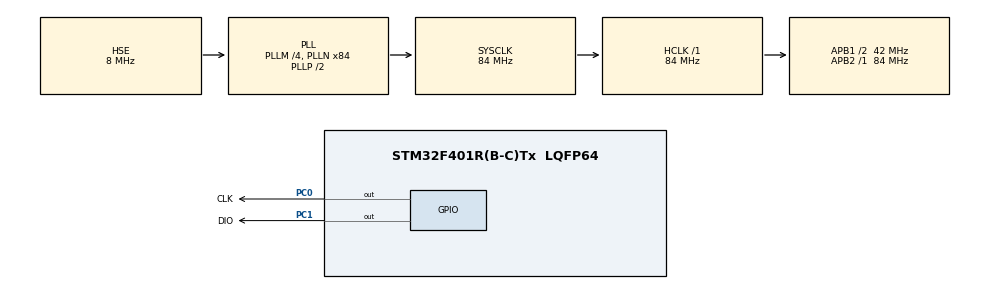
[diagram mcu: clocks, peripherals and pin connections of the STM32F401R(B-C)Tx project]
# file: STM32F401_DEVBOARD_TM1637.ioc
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Mcu.Family=STM32F4
Mcu.Name=STM32F401R(B-C)Tx
Mcu.Package=LQFP64
NVIC.PriorityGroup=NVIC_PRIORITYGROUP_4
PA13.Mode=Serial_Wire
PA13.Signal=SYS_JTMS-SWDIO
PA14.Mode=Serial_Wire
PA14.Signal=SYS_JTCK-SWCLK
PC0.GPIO_Label=CLK
PC0.GPIO_PuPd=GPIO_PULLUP
PC0.Signal=GPIO_Output
PC1.GPIO_Label=DIO
PC1.GPIO_PuPd=GPIO_PULLUP
PC1.Signal=GPIO_Output
PC14-OSC32_IN.Mode=LSE-External-Oscillator
PC14-OSC32_IN.Signal=RCC_OSC32_IN
PC15-OSC32_OUT.Mode=LSE-External-Oscillator
PC15-OSC32_OUT.Signal=RCC_OSC32_OUT
PH0\ -\ OSC_IN.Mode=HSE-External-Oscillator
PH0\ -\ OSC_IN.Signal=RCC_OSC_IN
PH1\ -\ OSC_OUT.Mode=HSE-External-Oscillator
PH1\ -\ OSC_OUT.Signal=RCC_OSC_OUT
ProjectManager.HeapSize=0x200
ProjectManager.StackSize=0x400
ProjectManager.TargetToolchain=STM32CubeIDE
RCC.48MHZClocksFreq_Value=42000000
RCC.AHBFreq_Value=84000000
RCC.APB1CLKDivider=RCC_HCLK_DIV2
RCC.APB1Freq_Value=42000000
RCC.APB1TimFreq_Value=84000000
RCC.APB2Freq_Value=84000000
RCC.APB2TimFreq_Value=84000000
RCC.CortexFreq_Value=84000000
RCC.HCLKFreq_Value=84000000
RCC.HSE_VALUE=8000000
RCC.HSI_VALUE=16000000
RCC.PLLM=4
RCC.PLLN=84
RCC.PLLSourceVirtual=RCC_PLLSOURCE_HSE
RCC.SYSCLKFreq_VALUE=84000000
RCC.SYSCLKSource=RCC_SYSCLKSOURCE_PLLCLK
RCC.VCOOutputFreq_Value=168000000
board=custom

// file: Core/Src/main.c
/* USER CODE BEGIN Header */
/**
  ******************************************************************************
  * @file           : main.c
  * @brief          : Main program body
  ******************************************************************************
  * @attention
  *
  * Copyright (c) 2025 STMicroelectronics.
  * All rights reserved.
  *
  * This software is licensed under terms that can be found in the LICENSE file
  * in the root directory of this software component.
  * If no LICENSE file comes with this software, it is provided AS-IS.
  *
  ******************************************************************************
  */
/* USER CODE END Header */
#include "main.h"
#include "gpio.h"

/* USER CODE BEGIN Includes */

#include "TM1637/TM1637.h"

/* USER CODE END Includes */

/* USER CODE BEGIN PM */

#define BRIGHTNESS 05

/* USER CODE END PM */

/* USER CODE BEGIN PV */

TM1637_t TM1637;
char TxBuffer[5];

/* USER CODE END PV */

void SystemClock_Config(void);

int main(void)
{

  /* MCU Configuration--------------------------------------------------------*/

  /* Reset of all peripherals, Initializes the Flash interface and the Systick. */
  HAL_Init();

  /* Configure the system clock */
  SystemClock_Config();

  /* Initialize all configured peripherals */
  MX_GPIO_Init();

  /* Infinite loop */
  /* USER CODE BEGIN WHILE */

  TM1637_init(&TM1637, CLK_GPIO_Port, CLK_Pin, DIO_GPIO_Port, DIO_Pin); // инициализация портов дисплея
  TM1637_set(&TM1637, BRIGHTNESS);
  TM1637_point(&TM1637, false);                             // точки отключаем

  while (1)
  {
    /* USER CODE END WHILE */

    /* USER CODE BEGIN 3 */

    TM1637_displayFloat(&TM1637, 12.38, 2);
    HAL_Delay(1000);

    TxBuffer[0] = 'E';
    TxBuffer[1] = '2';
    TxBuffer[2] = '1';
    TxBuffer[3] = '*';

    TM1637_display(&TM1637, TxBuffer);
    HAL_Delay(1000);

    int16_t temp = 173;
    TM1637_displayTemp (&TM1637, temp);
    HAL_Delay(1000);

    temp = 43;
    TM1637_displayTemp (&TM1637, temp);
    HAL_Delay(1000);

    temp = 9;
    TM1637_displayTemp (&TM1637, temp);
    HAL_Delay(1000);

    temp = -6;
    TM1637_displayTemp (&TM1637, temp);
    HAL_Delay(1000);

    temp = -27;
    TM1637_displayTemp (&TM1637, temp);
    HAL_Delay(1000);
  }
  /* USER CODE END 3 */
}

void SystemClock_Config(void)
{
  RCC_OscInitTypeDef RCC_OscInitStruct = {0};
  RCC_ClkInitTypeDef RCC_ClkInitStruct = {0};

  /** Configure the main internal regulator output voltage
  */
  __HAL_RCC_PWR_CLK_ENABLE();
  __HAL_PWR_VOLTAGESCALING_CONFIG(PWR_REGULATOR_VOLTAGE_SCALE2);

  /** Initializes the RCC Oscillators according to the specified parameters
  * in the RCC_OscInitTypeDef structure.
  */
  RCC_OscInitStruct.OscillatorType = RCC_OSCILLATORTYPE_HSE;
  RCC_OscInitStruct.HSEState = RCC_HSE_ON;
  RCC_OscInitStruct.PLL.PLLState = RCC_PLL_ON;
  RCC_OscInitStruct.PLL.PLLSource = RCC_PLLSOURCE_HSE;
  RCC_OscInitStruct.PLL.PLLM = 4;
  RCC_OscInitStruct.PLL.PLLN = 84;
  RCC_OscInitStruct.PLL.PLLP = RCC_PLLP_DIV2;
  RCC_OscInitStruct.PLL.PLLQ = 4;
  if (HAL_RCC_OscConfig(&RCC_OscInitStruct) != HAL_OK)
  {
    Error_Handler();
  }

  /** Initializes the CPU, AHB and APB buses clocks
  */
  RCC_ClkInitStruct.ClockType = RCC_CLOCKTYPE_HCLK|RCC_CLOCKTYPE_SYSCLK
                              |RCC_CLOCKTYPE_PCLK1|RCC_CLOCKTYPE_PCLK2;
  RCC_ClkInitStruct.SYSCLKSource = RCC_SYSCLKSOURCE_PLLCLK;
  RCC_ClkInitStruct.AHBCLKDivider = RCC_SYSCLK_DIV1;
  RCC_ClkInitStruct.APB1CLKDivider = RCC_HCLK_DIV2;
  RCC_ClkInitStruct.APB2CLKDivider = RCC_HCLK_DIV1;

  if (HAL_RCC_ClockConfig(&RCC_ClkInitStruct, FLASH_LATENCY_2) != HAL_OK)
  {
    Error_Handler();
  }
}

void Error_Handler(void)
{
  __disable_irq();
  while (1)
  {
  }
}
